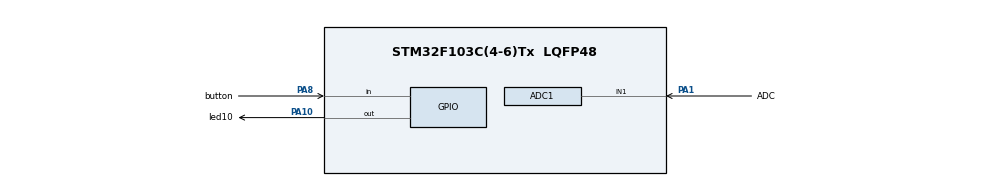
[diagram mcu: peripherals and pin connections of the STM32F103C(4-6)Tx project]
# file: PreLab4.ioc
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ADC1.Channel-1\#ChannelRegularConversion=ADC_CHANNEL_1
ADC1.NbrOfConversionFlag=1
ADC1.Rank-1\#ChannelRegularConversion=1
ADC1.SamplingTime-1\#ChannelRegularConversion=ADC_SAMPLETIME_1CYCLE_5
ADC1.master=1
Mcu.Family=STM32F1
Mcu.Name=STM32F103C(4-6)Tx
Mcu.Package=LQFP48
NVIC.PriorityGroup=NVIC_PRIORITYGROUP_4
PA1.GPIO_Label=ADC
PA1.Signal=ADCx_IN1
PA10.GPIO_Label=led10
PA10.Signal=GPIO_Output
PA8.GPIO_Label=button
PA8.GPIO_PuPd=GPIO_PULLDOWN
PA8.Signal=GPIO_Input
PD0-OSC_IN.Mode=HSE-External-Oscillator
PD0-OSC_IN.Signal=RCC_OSC_IN
PD1-OSC_OUT.Mode=HSE-External-Oscillator
PD1-OSC_OUT.Signal=RCC_OSC_OUT
ProjectManager.HeapSize=0x200
ProjectManager.StackSize=0x400
ProjectManager.TargetToolchain=MDK-ARM V5.32
RCC.APB1Freq_Value=8000000
RCC.APB2Freq_Value=8000000
SH.ADCx_IN1.0=ADC1_IN1,IN1
VP_SYS_VS_ND.Mode=No_Debug
board=custom

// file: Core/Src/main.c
/* USER CODE BEGIN Header */
/**
  ******************************************************************************
  * @file           : main.c
  * @brief          : Main program body
  ******************************************************************************
  * @attention
  *
  * Copyright (c) 2025 STMicroelectronics.
  * All rights reserved.
  *
  * This software is licensed under terms that can be found in the LICENSE file
  * in the root directory of this software component.
  * If no LICENSE file comes with this software, it is provided AS-IS.
  *
  ******************************************************************************
  */
/* USER CODE END Header */
#include "main.h"

ADC_HandleTypeDef hadc1;

void SystemClock_Config(void);
static void MX_GPIO_Init(void);
static void MX_ADC1_Init(void);

/* USER CODE BEGIN 0 */

	uint32_t adc_val;

/* USER CODE END 0 */

int main(void)
{

  /* MCU Configuration--------------------------------------------------------*/

  /* Reset of all peripherals, Initializes the Flash interface and the Systick. */
  HAL_Init();

  /* Configure the system clock */
  SystemClock_Config();

  /* Initialize all configured peripherals */
  MX_GPIO_Init();
  MX_ADC1_Init();

		HAL_ADCEx_Calibration_Start(&hadc1);

		GPIO_PinState button_state = GPIO_PIN_RESET;
		GPIO_PinState last_button_state= GPIO_PIN_RESET;
  /* Infinite loop */
  /* USER CODE BEGIN WHILE */
  while (1)
  {
		last_button_state = button_state;
		button_state = HAL_GPIO_ReadPin(button_GPIO_Port, button_Pin);

		adc_val = 0;
		HAL_ADC_Start(&hadc1);
		if(button_state == last_button_state || button_state == GPIO_PIN_RESET) continue;
		last_button_state = button_state;

		if((HAL_ADC_PollForConversion(&hadc1, 100) == HAL_OK)){
					adc_val = HAL_ADC_GetValue(&hadc1);
					if(adc_val >= 0x745)
								HAL_GPIO_WritePin(GPIOA, led10_Pin, GPIO_PIN_SET);
								HAL_Delay(500);
								HAL_GPIO_WritePin(GPIOA, led10_Pin, GPIO_PIN_RESET);
		}
		HAL_Delay(1000);

		HAL_ADC_Stop(&hadc1);

  }
  /* USER CODE END 3 */
}

void SystemClock_Config(void)
{
  RCC_OscInitTypeDef RCC_OscInitStruct = {0};
  RCC_ClkInitTypeDef RCC_ClkInitStruct = {0};
  RCC_PeriphCLKInitTypeDef PeriphClkInit = {0};

  /** Initializes the RCC Oscillators according to the specified parameters
  * in the RCC_OscInitTypeDef structure.
  */
  RCC_OscInitStruct.OscillatorType = RCC_OSCILLATORTYPE_HSI;
  RCC_OscInitStruct.HSIState = RCC_HSI_ON;
  RCC_OscInitStruct.HSICalibrationValue = RCC_HSICALIBRATION_DEFAULT;
  RCC_OscInitStruct.PLL.PLLState = RCC_PLL_NONE;
  if (HAL_RCC_OscConfig(&RCC_OscInitStruct) != HAL_OK)
  {
    Error_Handler();
  }

  /** Initializes the CPU, AHB and APB buses clocks
  */
  RCC_ClkInitStruct.ClockType = RCC_CLOCKTYPE_HCLK|RCC_CLOCKTYPE_SYSCLK
                              |RCC_CLOCKTYPE_PCLK1|RCC_CLOCKTYPE_PCLK2;
  RCC_ClkInitStruct.SYSCLKSource = RCC_SYSCLKSOURCE_HSI;
  RCC_ClkInitStruct.AHBCLKDivider = RCC_SYSCLK_DIV1;
  RCC_ClkInitStruct.APB1CLKDivider = RCC_HCLK_DIV1;
  RCC_ClkInitStruct.APB2CLKDivider = RCC_HCLK_DIV1;

  if (HAL_RCC_ClockConfig(&RCC_ClkInitStruct, FLASH_LATENCY_0) != HAL_OK)
  {
    Error_Handler();
  }
  PeriphClkInit.PeriphClockSelection = RCC_PERIPHCLK_ADC;
  PeriphClkInit.AdcClockSelection = RCC_ADCPCLK2_DIV2;
  if (HAL_RCCEx_PeriphCLKConfig(&PeriphClkInit) != HAL_OK)
  {
    Error_Handler();
  }
}

static void MX_ADC1_Init(void)
{

  ADC_ChannelConfTypeDef sConfig = {0};

  /** Common config
  */
  hadc1.Instance = ADC1;
  hadc1.Init.ScanConvMode = ADC_SCAN_DISABLE;
  hadc1.Init.ContinuousConvMode = DISABLE;
  hadc1.Init.DiscontinuousConvMode = DISABLE;
  hadc1.Init.ExternalTrigConv = ADC_SOFTWARE_START;
  hadc1.Init.DataAlign = ADC_DATAALIGN_RIGHT;
  hadc1.Init.NbrOfConversion = 1;
  if (HAL_ADC_Init(&hadc1) != HAL_OK)
  {
    Error_Handler();
  }

  /** Configure Regular Channel
  */
  sConfig.Channel = ADC_CHANNEL_1;
  sConfig.Rank = ADC_REGULAR_RANK_1;
  sConfig.SamplingTime = ADC_SAMPLETIME_1CYCLE_5;
  if (HAL_ADC_ConfigChannel(&hadc1, &sConfig) != HAL_OK)
  {
    Error_Handler();
  }

}

static void MX_GPIO_Init(void)
{
  GPIO_InitTypeDef GPIO_InitStruct = {0};

  /* GPIO Ports Clock Enable */
  __HAL_RCC_GPIOD_CLK_ENABLE();
  __HAL_RCC_GPIOA_CLK_ENABLE();

  /*Configure GPIO pin Output Level */
  HAL_GPIO_WritePin(led10_GPIO_Port, led10_Pin, GPIO_PIN_RESET);

  /*Configure GPIO pin : button_Pin */
  GPIO_InitStruct.Pin = button_Pin;
  GPIO_InitStruct.Mode = GPIO_MODE_INPUT;
  GPIO_InitStruct.Pull = GPIO_PULLDOWN;
  HAL_GPIO_Init(button_GPIO_Port, &GPIO_InitStruct);

  /*Configure GPIO pin : led10_Pin */
  GPIO_InitStruct.Pin = led10_Pin;
  GPIO_InitStruct.Mode = GPIO_MODE_OUTPUT_PP;
  GPIO_InitStruct.Pull = GPIO_NOPULL;
  GPIO_InitStruct.Speed = GPIO_SPEED_FREQ_LOW;
  HAL_GPIO_Init(led10_GPIO_Port, &GPIO_InitStruct);

}

void Error_Handler(void)
{
  __disable_irq();
  while (1)
  {
  }
}
